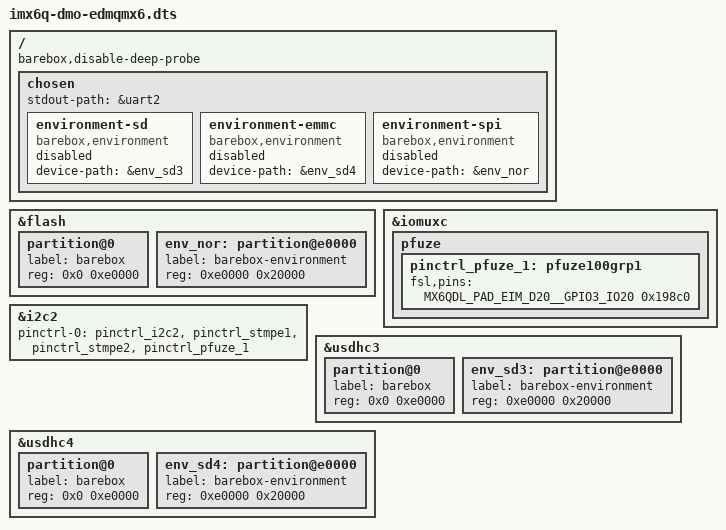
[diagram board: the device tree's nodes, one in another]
/*
 * Copyright 2011 Freescale Semiconductor, Inc.
 * Copyright 2011 Linaro Ltd.
 * Copyright 2013-2014 Data-Modul AG
 *
 * The code contained herein is licensed under the GNU General Public
 * License. You may obtain a copy of the GNU General Public License
 * Version 2 or later at the following locations:
 *
 * http://www.opensource.org/licenses/gpl-license.html
 * http://www.gnu.org/copyleft/gpl.html
 */

#include <arm/nxp/imx/imx6q-dmo-edmqmx6.dts>

/ {
	barebox,disable-deep-probe;

	chosen {
		stdout-path = &uart2;

		environment-sd {
			compatible = "barebox,environment";
			device-path = &env_sd3;
			status = "disabled";
		};

		environment-emmc {
			compatible = "barebox,environment";
			device-path = &env_sd4;
			status = "disabled";
		};

		environment-spi {
			compatible = "barebox,environment";
			device-path = &env_nor;
			status = "disabled";
		};
	};
};

&flash {
	#address-cells = <1>;
	#size-cells = <1>;

	partition@0 {
		label = "barebox";
		reg = <0x0 0xe0000>;
	};

	env_nor: partition@e0000 {
		label = "barebox-environment";
		reg = <0xe0000 0x20000>;
	};
};

&iomuxc {
	pfuze {
		pinctrl_pfuze_1: pfuze100grp1 {
			fsl,pins = <
				MX6QDL_PAD_EIM_D20__GPIO3_IO20 0x198c0
			>;
		};
	};
};

&i2c2 {
	pinctrl-0 = <&pinctrl_i2c2
	             &pinctrl_stmpe1
	             &pinctrl_stmpe2
	             &pinctrl_pfuze_1>;
};

&usdhc3 {
	#address-cells = <1>;
	#size-cells = <1>;

	partition@0 {
		label = "barebox";
		reg = <0x0 0xe0000>;
	};

	env_sd3: partition@e0000 {
		label = "barebox-environment";
		reg = <0xe0000 0x20000>;
	};
};

&usdhc4 {
	#address-cells = <1>;
	#size-cells = <1>;

	partition@0 {
		label = "barebox";
		reg = <0x0 0xe0000>;
	};

	env_sd4: partition@e0000 {
		label = "barebox-environment";
		reg = <0xe0000 0x20000>;
	};
};
